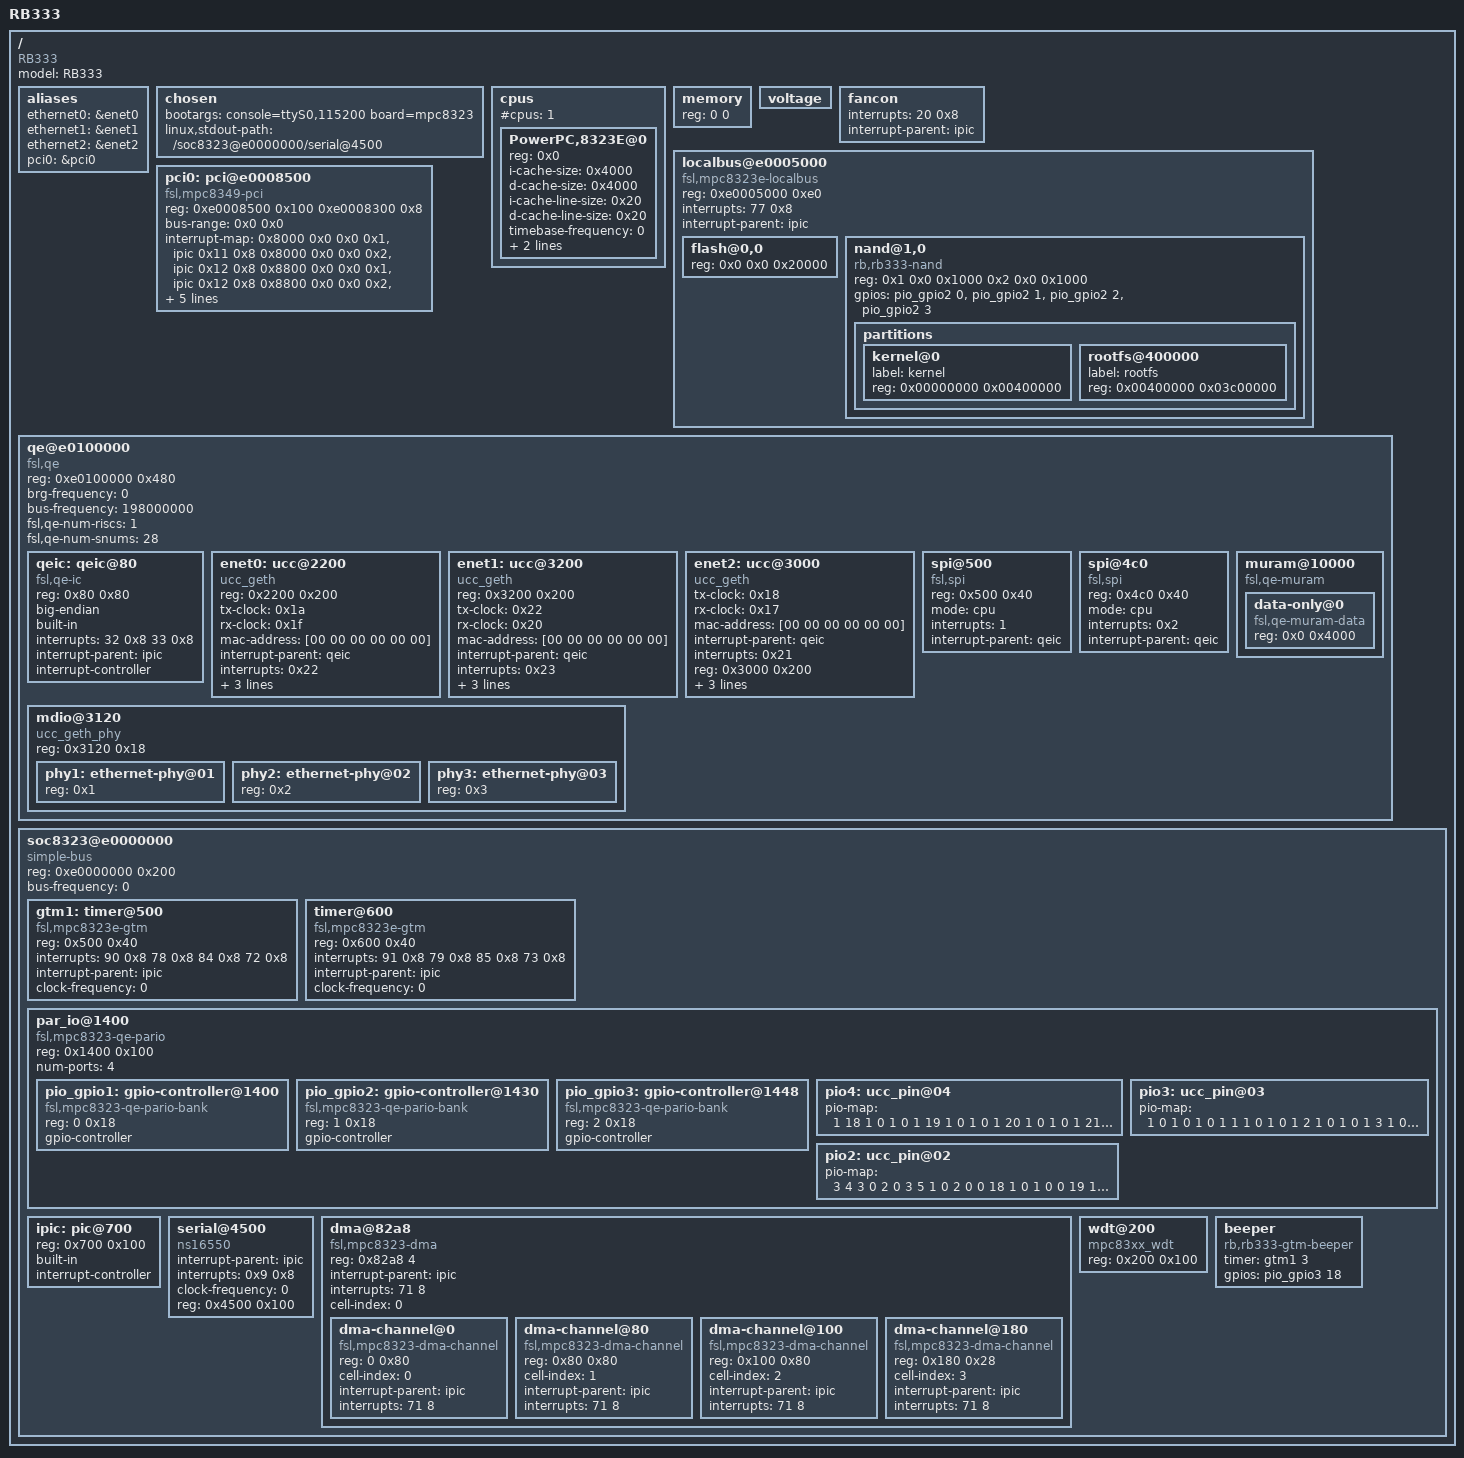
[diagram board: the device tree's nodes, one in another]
/*
 * RouterBOARD 333 series Device Tree Source
 *
 * Copyright (C) 2011 Noah Fontes <nfontes@invectorate.com>
 * Copyright (C) 2010 Alexandros C. Couloumbis <alex@ozo.com>
 * Copyright (C) 2009 Michael Guntsche <mike@it-loops.com>
 *
 * This program is free software; you can redistribute  it and/or modify it
 * under  the terms of  the GNU General  Public License as published by the
 * Free Software Foundation;  either version 2 of the  License, or (at your
 * option) any later version.
 */

/dts-v1/;

/ {
	model = "RB333";
	compatible = "RB333", "RBPPC";
	#size-cells = <1>;
	#address-cells = <1>;

	aliases {
		ethernet0 = &enet0;
		ethernet1 = &enet1;
		ethernet2 = &enet2;
		pci0 = &pci0;
	};

	chosen {
		bootargs = "console=ttyS0,115200 board=mpc8323";
		linux,stdout-path = "/soc8323@e0000000/serial@4500";
	};

	cpus {
		#cpus = <1>;
		#size-cells = <0>;
		#address-cells = <1>;

		PowerPC,8323E@0 {
			device_type = "cpu";
			reg = <0x0>;
			i-cache-size = <0x4000>;
			d-cache-size = <0x4000>;
			i-cache-line-size = <0x20>;
			d-cache-line-size = <0x20>;
			timebase-frequency = <0>; // Filled from the bootloader
			clock-frequency = <0>; // Filled from the bootloader
			32-bit;
		};
	};

	memory {
		device_type = "memory";
		reg = <0 0>; // Filled from the bootloader
	};

	voltage {
		//voltage_gpio = <&gpio3 0x11>;
	};

	fancon {
		interrupts = <20 0x8>;
		interrupt-parent = <&ipic>;
		//fan_on = <&gpio0 0x10>;
	};

	localbus@e0005000 {
		#address-cells = <2>;
		#size-cells = <1>;
		compatible = "fsl,mpc8323e-localbus", "fsl,pq2pro-localbus", "simple-bus";
		reg = <0xe0005000 0xe0>;
		interrupts = <77 0x8>;
		interrupt-parent = <&ipic>;
		// FIXME: May not be correct (actual) ranges
		ranges = <
			0x0 0x0 0xfe000000 0x00100000   // Flash
			0x1 0x0 0xf8000000 0x00008000   // NAND (IO base)
			0x2 0x0 0xf0000000 0x00008000>; // NAND (nNAND?)

		flash@0,0 {
			reg = <0x0 0x0 0x20000>;
		};

		nand@1,0 {
			compatible = "rb,rb333-nand", "rb,nand";
			reg = <
				0x1 0x0 0x1000   // IO
				0x2 0x0 0x1000>; // Sync

			gpios = <
				&pio_gpio2 0 0   // R/B
				&pio_gpio2 1 0   // nCE
				&pio_gpio2 2 0   // CLE
				&pio_gpio2 3 0>; // ALE

			partitions {
				#address-cells = <1>;
				#size-cells = <1>;

				kernel@0 {
					label = "kernel";
					reg = <0x00000000 0x00400000>;
				};
				rootfs@400000 {
					label = "rootfs";
					reg = <0x00400000 0x03c00000>;
				};
			};
		};
	};

	pci0: pci@e0008500 {
		#address-cells = <3>;
		#size-cells = <2>;
		#interrupt-cells = <1>;
		device_type = "pci";
		compatible = "fsl,mpc8349-pci";
		reg = <0xe0008500 0x100 0xe0008300 0x8>;
		ranges = <
			0x02000000 0x0 0x80000000
			0x80000000 0x0 0x20000000
			0x01000000 0x0 0x00000000
			0xd0000000 0x0 0x04000000>;
		bus-range = <0x0 0x0>;
		interrupt-map = <
			/* IDSEL 0x10 AD16 miniPCI slot 0 */
			0x8000 0x0 0x0 0x1 &ipic 0x11 0x8
			0x8000 0x0 0x0 0x2 &ipic 0x12 0x8

			/* IDSEL 0x11 AD17 miniPCI slot 1 */
			0x8800 0x0 0x0 0x1 &ipic 0x12 0x8
			0x8800 0x0 0x0 0x2 &ipic 0x13 0x8

			/* IDSEL 0x12 AD18  miniPCI slot 2 */
			0x9000 0x0 0x0 0x1 &ipic 0x13 0x8
			0x9000 0x0 0x0 0x2 &ipic 0x11 0x8>;
		interrupt-map-mask = <0xf800 0x0 0x0 0x7>;
		interrupt-parent = <&ipic>;
	};

	qe@e0100000 {
		#size-cells = <1>;
		#address-cells = <1>;
		device_type = "qe";
		compatible = "fsl,qe";
		reg = <0xe0100000 0x480>;
		ranges = <0x0 0xe0100000 0x100000>;
		brg-frequency = <0>;
		bus-frequency = <198000000>;
		fsl,qe-num-riscs = <1>;
		fsl,qe-num-snums = <28>;

		qeic: qeic@80 {
			#address-cells = <0>;
			#interrupt-cells = <1>;
			device_type = "qeic";
			compatible = "fsl,qe-ic";
			reg = <0x80 0x80>;
			big-endian;
			built-in;
			interrupts = <32 0x8 33 0x8>;
			interrupt-parent = <&ipic>;
			interrupt-controller;
		};

		enet0: ucc@2200 {
			device_type = "network";
			compatible = "ucc_geth";
			reg = <0x2200 0x200>;
			tx-clock = <0x1a>;
			rx-clock = <0x1f>;
			mac-address = [00 00 00 00 00 00]; // Filled from the bootloader
			interrupt-parent = <&qeic>;
			interrupts = <0x22>;
			device-id = <0x3>;
			phy-handle = <&phy2>;
			pio-handle = <&pio3>;
		};

		enet1: ucc@3200 {
			device_type = "network";
			compatible = "ucc_geth";
			reg = <0x3200 0x200>;
			tx-clock = <0x22>;
			rx-clock = <0x20>;
			mac-address = [00 00 00 00 00 00]; // Filled from the bootloader
			interrupt-parent = <&qeic>;
			interrupts = <0x23>;
			device-id = <0x4>;
			phy-handle = <&phy3>;
			pio-handle = <&pio4>;
		};

		enet2: ucc@3000 {
			tx-clock = <0x18>;
			rx-clock = <0x17>;
			mac-address = [00 00 00 00 00 00]; // Filled from the bootloader
			interrupt-parent = <&qeic>;
			interrupts = <0x21>;
			reg = <0x3000 0x200>;
			device-id = <0x2>;
			compatible = "ucc_geth";
			device_type = "network";
			phy-handle = <&phy1>;
			pio-handle = <&pio2>;
		};

		mdio@3120 {
			#address-cells = <1>;
			#size-cells = <0>;
			compatible = "ucc_geth_phy";
			device_type = "mdio";
			reg = <0x3120 0x18>;

			phy1: ethernet-phy@01 {
				device_type = "ethernet-phy";
				reg = <0x1>;
			};

			phy2: ethernet-phy@02 {
				device_type = "ethernet-phy";
				reg = <0x2>;
			};

			phy3: ethernet-phy@03 {
				device_type = "ethernet-phy";
				reg = <0x3>;
			};
		};

		spi@500 {
			device_type = "spi";
			compatible = "fsl,spi";
			reg = <0x500 0x40>;
			mode = "cpu";
			interrupts = <1>;
			interrupt-parent = <&qeic>;
		};

		spi@4c0 {
			device_type = "spi";
			compatible = "fsl,spi";
			reg = <0x4c0 0x40>;
			mode = "cpu";
			interrupts = <0x2>;
			interrupt-parent = <&qeic>;
		};

		muram@10000 {
			#address-cells = <1>;
			#size-cells = <1>;
			device_type = "muram";
			compatible = "fsl,qe-muram", "fsl,cpm-muram";
			ranges = <0x0 0x10000 0x4000>;

			data-only@0 {
				compatible = "fsl,qe-muram-data",
					"fsl,cpm-muram-data";
				reg = <0x0 0x4000>;
			};
		};
	};

	soc8323@e0000000 {
		#interrupt-cells = <0x2>;
		#size-cells = <1>;
		#address-cells = <1>;
		device_type = "soc";
		compatible = "simple-bus";
		reg = <0xe0000000 0x200>;
		ranges = <0x0 0xe0000000 0x100000>;
		bus-frequency = <0>; // Filled from the bootloader

		gtm1: timer@500 {
			compatible = "fsl,mpc8323e-gtm", "fsl,gtm";
			reg = <0x500 0x40>;
			interrupts = <90 0x8 78 0x8 84 0x8 72 0x8>;
			interrupt-parent = <&ipic>;
			clock-frequency = <0>; // Filled from the bootloader
		};

		timer@600 {
			compatible = "fsl,mpc8323e-gtm", "fsl,gtm";
			reg = <0x600 0x40>;
			interrupts = <91 0x8 79 0x8 85 0x8 73 0x8>;
			interrupt-parent = <&ipic>;
			clock-frequency = <0>; // Filled from the bootloader
		};

		par_io@1400 {
			#address-cells = <1>;
			#size-cells = <1>;
			device_type = "par_io";
			compatible = "fsl,mpc8323-qe-pario";
			reg = <0x1400 0x100>;
			ranges = <
				0x0 0x1400 0x18
				0x1 0x1430 0x18
				0x2 0x1448 0x18>;
			num-ports = <4>;

			pio_gpio1: gpio-controller@1400 {
				#gpio-cells = <2>;
				compatible = "fsl,mpc8323-qe-pario-bank";
				reg = <0 0x18>;
				gpio-controller;
			};

			pio_gpio2: gpio-controller@1430 {
				#gpio-cells = <2>;
				compatible = "fsl,mpc8323-qe-pario-bank";
				reg = <1 0x18>;
				gpio-controller;
			};

			pio_gpio3: gpio-controller@1448 {
				#gpio-cells = <2>;
				compatible = "fsl,mpc8323-qe-pario-bank";
				reg = <2 0x18>;
				gpio-controller;
			};

			pio4: ucc_pin@04 {
				pio-map = <
			/* port  pin  dir  open_drain  assignment  has_irq */
					1 18 1 0 1 0 
					1 19 1 0 1 0 
					1 20 1 0 1 0 
					1 21 1 0 1 0 
					1 30 1 0 1 0 
					3 20 2 0 1 0 
					1 30 2 0 1 0 
					1 31 2 0 1 0 
					1 22 2 0 1 0 
					1 23 2 0 1 0 
					1 24 2 0 1 0 
					1 25 2 0 1 0 
					1 28 2 0 1 0 
					1 26 2 0 1 0 
					3 21 2 0 1 0>;
			};

			pio3: ucc_pin@03 {
				pio-map = <
			/* port  pin  dir  open_drain  assignment  has_irq */
					1 0  1 0 1 0 
					1 1  1 0 1 0 
					1 2  1 0 1 0 
					1 3  1 0 1 0 
					1 12 1 0 1 0 
					3 24 2 0 1 0 
					1 11 2 0 1 0 
					1 13 2 0 1 0 
					1 4  2 0 1 0 
					1 5  2 0 1 0 
					1 6  2 0 1 0 
					1 7  2 0 1 0 
					1 10 2 0 1 0 
					1 8  2 0 1 0 
					3 29 2 0 1 0>;
			};

			pio2: ucc_pin@02 {
				pio-map = <
			/* port  pin  dir  open_drain  assignment  has_irq */
					3 4  3 0 2 0 
					3 5  1 0 2 0 
					0 18 1 0 1 0 
					0 19 1 0 1 0 
					0 20 1 0 1 0 
					0 21 1 0 1 0 
					0 30 1 0 1 0 
					3 6  2 0 1 0 
					0 29 2 0 1 0 
					0 31 2 0 1 0 
					0 22 2 0 1 0 
					0 23 2 0 1 0 
					0 24 2 0 1 0 
					0 25 2 0 1 0 
					0 28 2 0 1 0 
					0 26 2 0 1 0 
					3 31 2 0 1 0>;
			};
		};

		ipic: pic@700 {
			#address-cells = <0x0>;
			#interrupt-cells = <0x2>;
			device_type = "ipic";
			reg = <0x700 0x100>;
			built-in;
			interrupt-controller;
		};

		serial@4500 {
			interrupt-parent = <&ipic>;
			interrupts = <0x9 0x8>;
			clock-frequency = <0>; // Filled from the bootloader
			reg = <0x4500 0x100>;
			compatible = "ns16550";
			device_type = "serial";
		};

		dma@82a8 {
			#address-cells = <1>;
			#size-cells = <1>;
			compatible = "fsl,mpc8323-dma", "fsl,elo-dma";
			reg = <0x82a8 4>;
			ranges = <0 0x8100 0x1a8>;
			interrupt-parent = <&ipic>;
			interrupts = <71 8>;
			cell-index = <0>;
			dma-channel@0 {
				compatible = "fsl,mpc8323-dma-channel", "fsl,elo-dma-channel";
				reg = <0 0x80>;
				cell-index = <0>;
				interrupt-parent = <&ipic>;
				interrupts = <71 8>;
			};
			dma-channel@80 {
				compatible = "fsl,mpc8323-dma-channel", "fsl,elo-dma-channel";
				reg = <0x80 0x80>;
				cell-index = <1>;
				interrupt-parent = <&ipic>;
				interrupts = <71 8>;
			};
			dma-channel@100 {
				compatible = "fsl,mpc8323-dma-channel", "fsl,elo-dma-channel";
				reg = <0x100 0x80>;
				cell-index = <2>;
				interrupt-parent = <&ipic>;
				interrupts = <71 8>;
			};
			dma-channel@180 {
				compatible = "fsl,mpc8323-dma-channel", "fsl,elo-dma-channel";
				reg = <0x180 0x28>;
				cell-index = <3>;
				interrupt-parent = <&ipic>;
				interrupts = <71 8>;
			};
		};

		wdt@200 {
			reg = <0x200 0x100>;
			compatible = "mpc83xx_wdt";
			device_type = "watchdog";
		};

		beeper {
			compatible = "rb,rb333-gtm-beeper", "rb,gtm-beeper";
			timer = <&gtm1 3>;
			gpios = <&pio_gpio3 18 0>;
		};
	};
};
